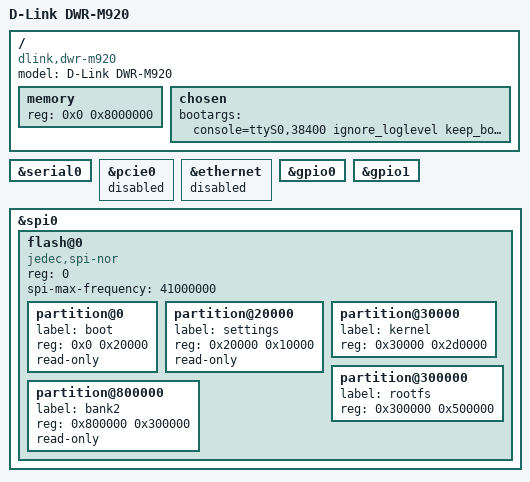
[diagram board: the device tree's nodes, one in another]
// SPDX-License-Identifier: GPL-2.0
/*
 * D-Link DWR-M920 (Zain build, hw A1) - RTL8197FH-VG, 128 MB DDR2, 16 MB EN25QH128A.
 * STAGE 1 SKETCH: serial console + flash map only. Not built, not booted.
 * Everything below is taken from the stock serial log and the SPI dump; items
 * marked TODO are not known yet.
 */
/dts-v1/;

#include "RTL8197F.dtsi"

/ {
	compatible = "dlink,dwr-m920", "realtek,rtl8197f-soc";
	model = "D-Link DWR-M920";

	memory {
		device_type = "memory";
		reg = <0x0 0x8000000>;		/* 128 MB, bootloader: "Detect dram size = 128MB" */
	};

	chosen {
		bootargs = "console=ttyS0,38400 ignore_loglevel keep_bootcon";	/* stock: console=ttyS0,38400; extra flags = diagnostics */
	};

	/* TODO: LEDs / buttons / modem reset+power GPIOs - not in the logs; decode from
	 * the stock binaries (libapmib/boa/sysconf) or the SDK's dev_leds_gpio.c. */
};

/* test 6: with the UART interrupt connected the box floods "serial8250: too much work for irq17" as soon
 * as the console tty is opened (test 5) and the shell starves. Run the port polled instead:
 * patches-4.14/0010 lets 8250_dw fall back to the 8250 core's timer when the node has no interrupt. */
&serial0 {
	/delete-property/ interrupts;
	/delete-property/ interrupt-parent;
};

/* no PCIe device on this board (stock: "PCIE -> Cannot LinkUP") */
&pcie0 { status = "disabled"; };

/* test 3: the stock bootloader prints "disable ETH during boot", so the switch core is held in
 * reset and the DIR-842 NIC driver (written for an external RTL8367S) is the prime suspect for the
 * silent hang after the console comes up. Keep it off until the internal-switch work in stage 2. */
&ethernet { status = "disabled"; };

&gpio0 { status = "okay"; };
&gpio1 { status = "okay"; };

/* TODO(stage 2): internal 5-port switch. Stock log: eth1 = WAN (port mask 0x01);
 * eth0/eth2/eth3/eth4 = LAN (masks 0x02/0x04/0x08/0x10). No external switch.
 * The DIR-842 rtl819x-eth driver assumes an RGMII trunk to an RTL8367S and needs an
 * "internal PHY" mode - see docs/M920-HARDWARE.md. */

/* TODO(stage 2): USB. On-chip EHCI @0x18021000 + OHCI @0x18020000, IRQ 21, one port,
 * Quectel module 2c7c:6005 attached directly. PHY init values are in docs/M920-HARDWARE.md. */

&spi0 {
	status = "okay";

	flash@0 {
		#address-cells = <1>;
		#size-cells = <1>;
		compatible = "jedec,spi-nor";	/* JEDEC id 1C7018 (EON EN25QH128A) */
		reg = <0>;
		spi-max-frequency = <41000000>;	/* stock runs 75 MHz; stay conservative first */

		/* Stock map (bank 1). Bootloader/hw-settings/config are never touched. */
		partition@0 {
			label = "boot";
			reg = <0x0 0x20000>;
			read-only;
		};

		partition@20000 {
			label = "settings";		/* 'H601' hw settings (MAC, RF calibration) @0x20000, 'COMPCS' config @0x2a000 */
			reg = <0x20000 0x10000>;
			read-only;
		};

		partition@30000 {
			label = "kernel";		/* 'cr6c' image, load 0x80a00000 */
			reg = <0x30000 0x2d0000>;
		};

		partition@300000 {
			label = "rootfs";		/* squashfs + 2-byte checksum, read-only */
			reg = <0x300000 0x500000>;
		};

		/* Bank 2 boot/settings/kernel (0x800000-0xb00000) is left untouched: the stock loader may
		 * read it. The loader hangs on a bad bank 1 (no automatic fallback observed), so bank 2 is
		 * not a working fallback; the writable overlay is the "rootfs_data" that mtdsplit carves out behind the squashfs
		 * (0x460000-0x800000); the rootfs image is padded so its checksum stays inside the rootfs block. */
		partition@800000 {
			label = "bank2";
			reg = <0x800000 0x300000>;
			read-only;
		};
	};
};
